# PCIE_MSG_IRQ_REGS register map
Vendor: Texas Instruments
Peripheral module from a debugger description file (folder 66AK2G0x_66AK2G1x).
Registers are 32-bit, access per field, reset values left out (the file's numbers can be read two ways) unless marked. A register's access mark holds for its fields unless they carry their own. Offsets are as the file gives them; lines under a group give offsets from that group; [hi:lo] are bit positions; {n}, {i} and the like mark numbered series; 'fields as' and 'values as' point back to an identical list; <NAME> marks a mode.

## PCIE_MSG_IRQ_REGS
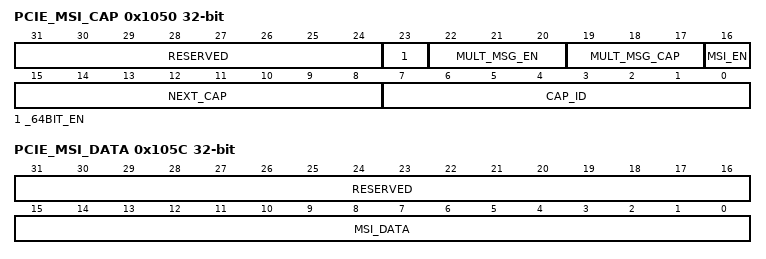
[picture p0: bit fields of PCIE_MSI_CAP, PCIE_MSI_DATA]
0x1050 PCIE_MSI_CAP
  [31:24] RESERVED ro — Reads return 0 and writes have no effect.
  [23] _64BIT_EN ro — 64-bit addressing enabled. Writable from internal bus interface.
  [22:20] MULT_MSG_EN rw — Multiple message enabled. Indicates that multiple message mode is enabled by software. Number of messages enabled must not be greater than multiple message capable value.
  [19:17] MULT_MSG_CAP ro — Multiple message capable. Writable from internal bus interface.
  [16] MSI_EN rw — MSI Enabled. When set, INTx must be disabled.
  [15:8] NEXT_CAP ro — Next capability pointer. By default, it points to PCI Express Capabilities structure. Writable from internal bus interface.
  [7:0] CAP_ID ro — MSI Capability ID.
0x1054 PCIE_MSI_LOW32 rw
  [31:0] LOW32_ADDR — Lower 32 bits address
0x1058 PCIE_MSI_UP32 rw
  [31:0] UP32_ADDR — Upper 32 bits address
0x105C PCIE_MSI_DATA
  [31:16] RESERVED ro — Reads return 0 and writes have no effect.
  [15:0] MSI_DATA rw
